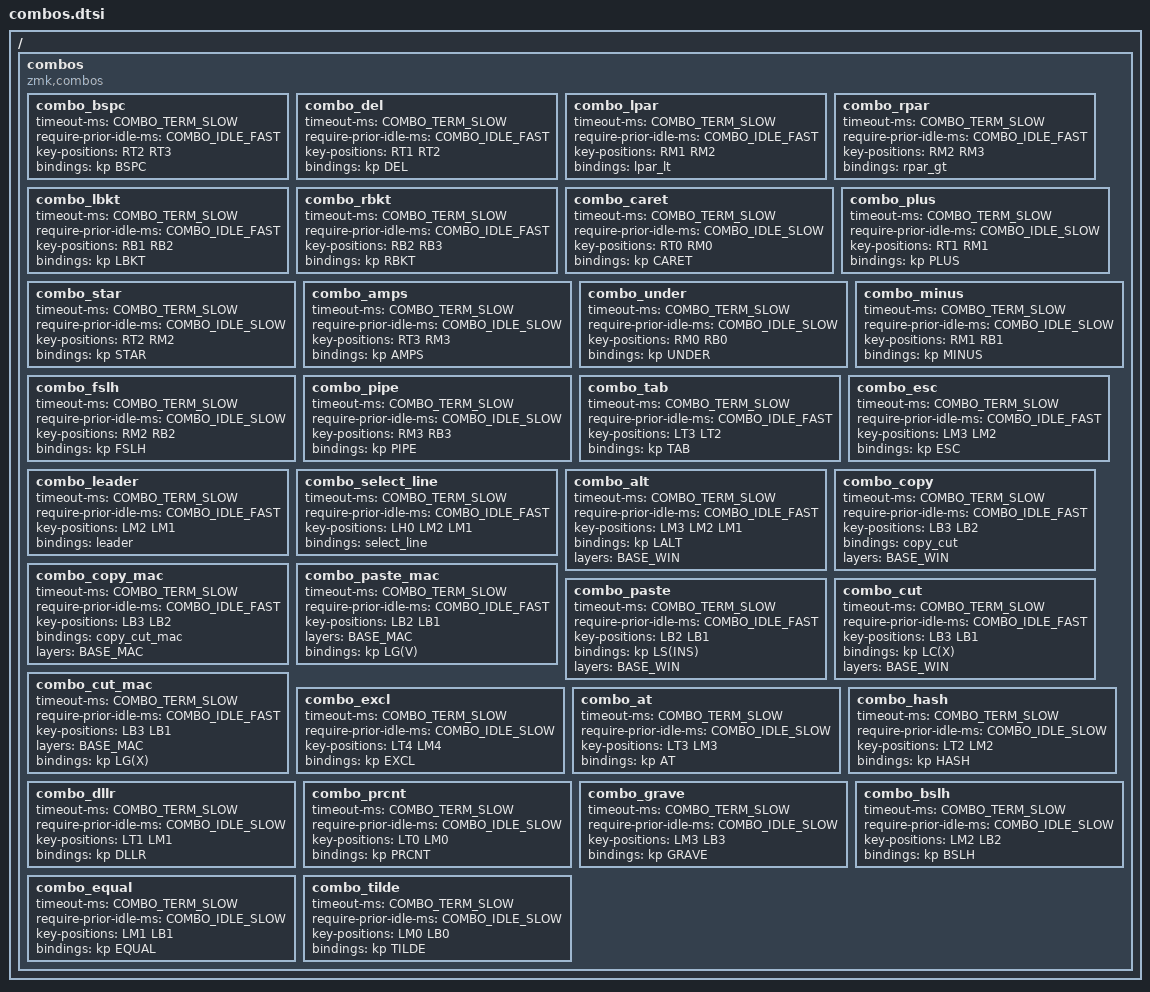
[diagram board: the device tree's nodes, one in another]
/*                              34 KEY MATRIX / LAYOUT MAPPING
╭────────────────────┬────────────────────╮ ╭─────────────────────┬─────────────────────╮
│  0   1   2   3   4 │  5   6   7   8   9 │ │ LT4 LT3 LT2 LT1 LT0 │ RT0 RT1 RT2 RT3 RT4 │
│ 10  11  12  13  14 │ 15  16  17  18  19 │ │ LM4 LM3 LM2 LM1 LM0 │ RM0 RM1 RM2 RM3 RM4 │
│ 20  21  22  23  24 │ 25  26  27  28  29 │ │ LB4 LB3 LB2 LB1 LB0 │ RB0 RB1 RB2 RB3 RB4 │
╰───────────╮ 30  31 │ 32  33 ╭───────────╯ ╰───────────╮ LH1 LH0 │ RH0 RH1 ╭───────────╯
            ╰────────┴────────╯                         ╰─────────┴─────────╯             
*/

#define COMBO_TERM_FAST 20
#define COMBO_TERM_SLOW 50
#define COMBO_TERM_VERY_SLOW 100
#define COMBO_IDLE_FAST 150
#define COMBO_IDLE_SLOW 50

/ {
	combos {
		compatible = "zmk,combos";
		
		/* Horizontal combos - right hand */
		combo_bspc {
			timeout-ms = <COMBO_TERM_SLOW>;
			require-prior-idle-ms = <COMBO_IDLE_FAST>;
			key-positions = <RT2 RT3>;
			bindings = <&kp BSPC>;
		};
		
		combo_del {
			timeout-ms = <COMBO_TERM_SLOW>;
			require-prior-idle-ms = <COMBO_IDLE_FAST>;
			key-positions = <RT1 RT2>;
			bindings = <&kp DEL>;
		};
		
		combo_lpar {
			timeout-ms = <COMBO_TERM_SLOW>;
			require-prior-idle-ms = <COMBO_IDLE_FAST>;
			key-positions = <RM1 RM2>;
			bindings = <&lpar_lt>;
		};
		
		combo_rpar {
			timeout-ms = <COMBO_TERM_SLOW>;
			require-prior-idle-ms = <COMBO_IDLE_FAST>;
			key-positions = <RM2 RM3>;
			bindings = <&rpar_gt>;
		};
		
		combo_lbkt {
			timeout-ms = <COMBO_TERM_SLOW>;
			require-prior-idle-ms = <COMBO_IDLE_FAST>;
			key-positions = <RB1 RB2>;
			bindings = <&kp LBKT>;
		};
		
		combo_rbkt {
			timeout-ms = <COMBO_TERM_SLOW>;
			require-prior-idle-ms = <COMBO_IDLE_FAST>;
			key-positions = <RB2 RB3>;
			bindings = <&kp RBKT>;
		};
		
		/* Vertical combos - right hand */
		combo_caret {
			timeout-ms = <COMBO_TERM_SLOW>;
			require-prior-idle-ms = <COMBO_IDLE_SLOW>;
			key-positions = <RT0 RM0>;
			bindings = <&kp CARET>;
		};
		
		combo_plus {
			timeout-ms = <COMBO_TERM_SLOW>;
			require-prior-idle-ms = <COMBO_IDLE_SLOW>;
			key-positions = <RT1 RM1>;
			bindings = <&kp PLUS>;
		};
		
		combo_star {
			timeout-ms = <COMBO_TERM_SLOW>;
			require-prior-idle-ms = <COMBO_IDLE_SLOW>;
			key-positions = <RT2 RM2>;
			bindings = <&kp STAR>;
		};
		
		combo_amps {
			timeout-ms = <COMBO_TERM_SLOW>;
			require-prior-idle-ms = <COMBO_IDLE_SLOW>;
			key-positions = <RT3 RM3>;
			bindings = <&kp AMPS>;
		};
		
		combo_under {
			timeout-ms = <COMBO_TERM_SLOW>;
			require-prior-idle-ms = <COMBO_IDLE_SLOW>;
			key-positions = <RM0 RB0>;
			bindings = <&kp UNDER>;
		};
		
		combo_minus {
			timeout-ms = <COMBO_TERM_SLOW>;
			require-prior-idle-ms = <COMBO_IDLE_SLOW>;
			key-positions = <RM1 RB1>;
			bindings = <&kp MINUS>;
		};
		
		combo_fslh {
			timeout-ms = <COMBO_TERM_SLOW>;
			require-prior-idle-ms = <COMBO_IDLE_SLOW>;
			key-positions = <RM2 RB2>;
			bindings = <&kp FSLH>;
		};
		
		combo_pipe {
			timeout-ms = <COMBO_TERM_SLOW>;
			require-prior-idle-ms = <COMBO_IDLE_SLOW>;
			key-positions = <RM3 RB3>;
			bindings = <&kp PIPE>;
		};
		
		/* Horizontal combos - left hand */
		combo_tab {
			timeout-ms = <COMBO_TERM_SLOW>;
			require-prior-idle-ms = <COMBO_IDLE_FAST>;
			key-positions = <LT3 LT2>;
			bindings = <&kp TAB>;
		};
		
		combo_esc {
			timeout-ms = <COMBO_TERM_SLOW>;
			require-prior-idle-ms = <COMBO_IDLE_FAST>;
			key-positions = <LM3 LM2>;
			bindings = <&kp ESC>;
		};
		
		combo_leader {
			timeout-ms = <COMBO_TERM_SLOW>;
			require-prior-idle-ms = <COMBO_IDLE_FAST>;
			key-positions = <LM2 LM1>;
			bindings = <&leader>;
		};
		
		combo_select_line {
			timeout-ms = <COMBO_TERM_SLOW>;
			require-prior-idle-ms = <COMBO_IDLE_FAST>;
			key-positions = <LH0 LM2 LM1>;
			bindings = <&select_line>;
		};
		
		combo_alt {
			timeout-ms = <COMBO_TERM_SLOW>;
			require-prior-idle-ms = <COMBO_IDLE_FAST>;
			key-positions = <LM3 LM2 LM1>;
			bindings = <&kp LALT>;
			layers = <BASE_WIN>;
		};
		
		combo_copy {
			timeout-ms = <COMBO_TERM_SLOW>;
			require-prior-idle-ms = <COMBO_IDLE_FAST>;
			key-positions = <LB3 LB2>;
			bindings = <&copy_cut>;
			layers = <BASE_WIN>;
		};
		
		combo_copy_mac{
			timeout-ms = <COMBO_TERM_SLOW>;
			require-prior-idle-ms = <COMBO_IDLE_FAST>;
			key-positions = <LB3 LB2>;
			bindings = <&copy_cut_mac>;
			layers = <BASE_MAC>;
		};
		
		combo_paste_mac{
			timeout-ms = <COMBO_TERM_SLOW>;
			require-prior-idle-ms = <COMBO_IDLE_FAST>;
			key-positions = <LB2 LB1>;
			layers = <BASE_MAC>;
			bindings = <&kp LG(V)>;
		};
		
		combo_paste {
			timeout-ms = <COMBO_TERM_SLOW>;
			require-prior-idle-ms = <COMBO_IDLE_FAST>;
			key-positions = <LB2 LB1>;
			bindings = <&kp LS(INS)>;
			layers = <BASE_WIN>;
		};

		combo_cut {
			timeout-ms = <COMBO_TERM_SLOW>;
			require-prior-idle-ms = <COMBO_IDLE_FAST>;
			key-positions = <LB3 LB1>;
			bindings = <&kp LC(X)>;
			layers = <BASE_WIN>;
		};
		
		combo_cut_mac{
			timeout-ms = <COMBO_TERM_SLOW>;
			require-prior-idle-ms = <COMBO_IDLE_FAST>;
			key-positions = <LB3 LB1>;
			layers = <BASE_MAC>;
			bindings = <&kp LG(X)>;
		};
		
		/* Vertical combos - left hand */
		combo_excl {
			timeout-ms = <COMBO_TERM_SLOW>;
			require-prior-idle-ms = <COMBO_IDLE_SLOW>;
			key-positions = <LT4 LM4>;
			bindings = <&kp EXCL>;
		};
		
		combo_at {
			timeout-ms = <COMBO_TERM_SLOW>;
			require-prior-idle-ms = <COMBO_IDLE_SLOW>;
			key-positions = <LT3 LM3>;
			bindings = <&kp AT>;
		};
		
		combo_hash {
			timeout-ms = <COMBO_TERM_SLOW>;
			require-prior-idle-ms = <COMBO_IDLE_SLOW>;
			key-positions = <LT2 LM2>;
			bindings = <&kp HASH>;
		};
		
		combo_dllr {
			timeout-ms = <COMBO_TERM_SLOW>;
			require-prior-idle-ms = <COMBO_IDLE_SLOW>;
			key-positions = <LT1 LM1>;
			bindings = <&kp DLLR>;
		};
		
		combo_prcnt {
			timeout-ms = <COMBO_TERM_SLOW>;
			require-prior-idle-ms = <COMBO_IDLE_SLOW>;
			key-positions = <LT0 LM0>;
			bindings = <&kp PRCNT>;
		};
		
		combo_grave {
			timeout-ms = <COMBO_TERM_SLOW>;
			require-prior-idle-ms = <COMBO_IDLE_SLOW>;
			key-positions = <LM3 LB3>;
			bindings = <&kp GRAVE>;
		};
		
		combo_bslh {
			timeout-ms = <COMBO_TERM_SLOW>;
			require-prior-idle-ms = <COMBO_IDLE_SLOW>;
			key-positions = <LM2 LB2>;
			bindings = <&kp BSLH>;
		};
		
		combo_equal {
			timeout-ms = <COMBO_TERM_SLOW>;
			require-prior-idle-ms = <COMBO_IDLE_SLOW>;
			key-positions = <LM1 LB1>;
			bindings = <&kp EQUAL>;
		};
		
		combo_tilde {
			timeout-ms = <COMBO_TERM_SLOW>;
			require-prior-idle-ms = <COMBO_IDLE_SLOW>;
			key-positions = <LM0 LB0>;
			bindings = <&kp TILDE>;
		};
	};
};
